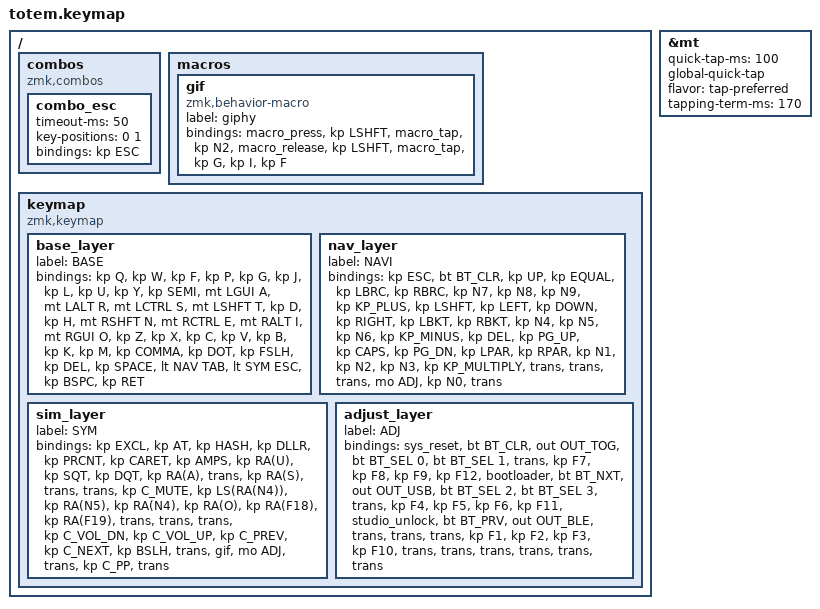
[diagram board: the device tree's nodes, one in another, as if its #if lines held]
//
//                                                        ▀▀▀▀▀     ▀▀▀▀▀          ▀▀█▀▀
//                                                        ▄▀▀▀▄  ▄  ▄▀▀▀▄  ▄  ▄▀▀▀▄  █  ▄▀▀▀▄
//                                                        █   █  █  █   █  █  █   █  █  █   █
//                                                         ▀▀▀   █   ▀▀▀   █   ▀▀▀   ▀   ▀▀▀
//                                                               █      ▄▄▄█▄▄▄    █   █  
//                                                               ▀      █  █  █     █▄█
//                                                             ▀▀▀▀▀    █  █  █      ▀
//                                                                      ▀  ▀  ▀
//
// ▄▄▄▄▄▄▄▄▄▄▄▄▄▄▄▄▄▄▄▄▄▄▄▄▄▄▄▄▄▄▄▄▄▄▄▄▄▄▄▄▄▄▄▄▄▄▄▄▄▄▄▄▄▄▄▄▄▄▄▄▄▄▄▄▄▄▄▄▄▄▄▄▄▄▄▄▄▄▄▄▄▄▄▄▄▄▄▄▄▄▄▄▄▄▄▄▄▄▄▄▄▄▄▄▄▄▄▄▄▄▄▄▄▄▄▄▄▄▄▄▄▄▄▄▄▄▄▄▄▄▄▄▄▄▄▄▄▄▄▄▄▄▄▄▄▄▄▄▄
       

#include <behaviors.dtsi>
#include <dt-bindings/zmk/keys.h>
#include <dt-bindings/zmk/bt.h>
#include <dt-bindings/zmk/outputs.h>

#define BASE 0
#define NAV  1
#define SYM  2
#define ADJ  3

&mt {
  quick-tap-ms = <100>;
  global-quick-tap;
  flavor = "tap-preferred";
  tapping-term-ms = <170>;
};

/ {
    combos {
            compatible = "zmk,combos";
            combo_esc {
                timeout-ms = <50>;
                key-positions = <0 1>;
                bindings = <&kp ESC>;
            };
    };

    macros {
        gif: gif {
            label = "giphy";
            compatible = "zmk,behavior-macro";
            #binding-cells = <0>;
            bindings
                = <&macro_press &kp LSHFT>
                , <&macro_tap &kp N2>
                , <&macro_release &kp LSHFT>
                , <&macro_tap &kp G &kp I &kp F>
                ;
        };
    };

        keymap {
                compatible = "zmk,keymap";
// ▄▄▄▄▄▄▄▄▄▄▄▄▄▄▄▄▄▄▄▄▄▄▄▄▄▄▄▄▄▄▄▄▄▄▄▄▄▄▄▄▄▄▄▄▄▄▄▄▄▄▄▄▄▄▄▄▄▄▄▄▄▄▄▄▄▄▄▄▄▄▄▄▄▄▄▄▄▄▄▄▄▄▄▄▄▄▄▄▄▄▄▄▄▄▄▄▄▄▄▄▄▄▄▄▄▄▄▄▄▄▄▄▄▄▄▄▄▄▄▄▄▄▄▄▄▄▄▄▄▄▄▄▄▄▄▄▄▄▄▄▄▄▄▄▄▄▄▄▄

                base_layer {
// ┏━━━━━━━━━━━━━━━━━━━━━━━━━━━━━━━━━━━━━━━┓
label= "BASE"                              ;
// ┗━━━━━━━━━━━━━━━━━━━━━━━━━━━━━━━━━━━━━━━┛
//             ┏━━━━━━━━━━━┳━━━━━━━━━━━┳━━━━━━━━━━━┳━━━━━━━━━━━┳━━━━━━━━━━━┓   ┏━━━━━━━━━━━┳━━━━━━━━━━━┳━━━━━━━━━━━┳━━━━━━━━━━━┳━━━━━━━━━━━┓
//             ┃     Q     ┃     W     ┃     F     ┃     P     ┃     G     ┃   ┃     J     ┃     L     ┃     U     ┃     Y     ┃     ;     ┃
//             ┣━━━━━━━━━━━╋━━━━━━━━━━━╋━━━━━━━━━━━╋━━━━━━━━━━━╋━━━━━━━━━━━┫   ┣━━━━━━━━━━━╋━━━━━━━━━━━╋━━━━━━━━━━━╋━━━━━━━━━━━╋━━━━━━━━━━━┫
//             ┃     A     ┃     R     ┃     S     ┃     T     ┃     D     ┃   ┃     H     ┃     N     ┃     E     ┃     I     ┃     O     ┃
// ┏━━━━━━━━━━━╋━━━━━━━━━━━╋━━━━━━━━━━━╋━━━━━━━━━━━╋━━━━━━━━━━━╋━━━━━━━━━━━┫   ┣━━━━━━━━━━━╋━━━━━━━━━━━╋━━━━━━━━━━━╋━━━━━━━━━━━╋━━━━━━━━━━━╋━━━━━━━━━━━┓
// ┃           ┃     Z     ┃     X     ┃     C     ┃     V     ┃     B     ┃   ┃     K     ┃     M     ┃     ,     ┃     .     ┃     /     ┃           ┃
// ┗━━━━━━━━━━━┻━━━━━━━━━━━┻━━━━━━━━━━━╋━━━━━━━━━━━╋━━━━━━━━━━━╋━━━━━━━━━━━┫   ┣━━━━━━━━━━━╋━━━━━━━━━━━╋━━━━━━━━━━━╋━━━━━━━━━━━┻━━━━━━━━━━━┻━━━━━━━━━━━┛
//                                     ┃    DEL    ┃   SPACE   ┃  TAB/NAV  ┃   ┃  ESC/SYM  ┃   BSPC    ┃   ENTER   ┃
//                                     ┗━━━━━━━━━━━┻━━━━━━━━━━━┻━━━━━━━━━━━┛   ┗━━━━━━━━━━━┻━━━━━━━━━━━┻━━━━━━━━━━━┛
 bindings = <
// ╷           ╷           ╷           ╷           ╷           ╷           ╷   ╷           ╷           ╷           ╷           ╷           ╷           ╷

                &kp Q       &kp W       &kp F       &kp P       &kp G           &kp J       &kp L       &kp U       &kp Y       &kp SEMI
                &mt LGUI A  &mt LALT R  &mt LCTRL S &mt LSHFT T &kp D           &kp H       &mt RSHFT N &mt RCTRL E &mt RALT I  &mt RGUI O
    &kp Z       &kp X       &kp C       &kp V       &kp B           &kp K       &kp M       &kp COMMA   &kp DOT     &kp FSLH    
                                        &kp DEL     &kp SPACE   &lt NAV TAB     &lt SYM ESC &kp BSPC    &kp RET
                        >;
                };

// ▄▄▄▄▄▄▄▄▄▄▄▄▄▄▄▄▄▄▄▄▄▄▄▄▄▄▄▄▄▄▄▄▄▄▄▄▄▄▄▄▄▄▄▄▄▄▄▄▄▄▄▄▄▄▄▄▄▄▄▄▄▄▄▄▄▄▄▄▄▄▄▄▄▄▄▄▄▄▄▄▄▄▄▄▄▄▄▄▄▄▄▄▄▄▄▄▄▄▄▄▄▄▄▄▄▄▄▄▄▄▄▄▄▄▄▄▄▄▄▄▄▄▄▄▄▄▄▄▄▄▄▄▄▄▄▄▄▄▄▄▄▄▄▄▄▄▄▄▄


                nav_layer {
// ┏━━━━━━━━━━━━━━━━━━━━━━━━━━━━━━━━━━━━━━━┓
label= "NAVI"                              ;
// ┗━━━━━━━━━━━━━━━━━━━━━━━━━━━━━━━━━━━━━━━┛
//             ┏━━━━━━━━━━━┳━━━━━━━━━━━┳━━━━━━━━━━━┳━━━━━━━━━━━┳━━━━━━━━━━━┓   ┏━━━━━━━━━━━┳━━━━━━━━━━━┳━━━━━━━━━━━┳━━━━━━━━━━━┳━━━━━━━━━━━┓
//             ┃           ┃           ┃     UP    ┃           ┃     {     ┃   ┃     }     ┃     7     ┃     8     ┃     9     ┃     +     ┃
//             ┣━━━━━━━━━━━╋━━━━━━━━━━━╋━━━━━━━━━━━╋━━━━━━━━━━━╋━━━━━━━━━━━┫   ┣━━━━━━━━━━━╋━━━━━━━━━━━╋━━━━━━━━━━━╋━━━━━━━━━━━╋━━━━━━━━━━━┫
//             ┃   SHIFT   ┃   LEFT    ┃    DOWN   ┃   RIGHT   ┃     [     ┃   ┃     ]     ┃     4     ┃     5     ┃     6     ┃     -     ┃
// ┏━━━━━━━━━━━╋━━━━━━━━━━━╋━━━━━━━━━━━╋━━━━━━━━━━━╋━━━━━━━━━━━╋━━━━━━━━━━━┫   ┣━━━━━━━━━━━╋━━━━━━━━━━━╋━━━━━━━━━━━╋━━━━━━━━━━━╋━━━━━━━━━━━╋━━━━━━━━━━━┓
// ┃           ┃           ┃   P UP    ┃  C LOCK   ┃  P DOWN   ┃     (     ┃   ┃     )     ┃     1     ┃     2     ┃     3     ┃     *     ┃           ┃
// ┗━━━━━━━━━━━┻━━━━━━━━━━━┻━━━━━━━━━━━╋━━━━━━━━━━━╋━━━━━━━━━━━╋━━━━━━━━━━━┫   ┣━━━━━━━━━━━╋━━━━━━━━━━━╋━━━━━━━━━━━╋━━━━━━━━━━━┻━━━━━━━━━━━┻━━━━━━━━━━━┛
//                                     ┃           ┃    TAB    ┃    SPC    ┃   ┃    DEL    ┃     0     ┃           ┃
//                                     ┗━━━━━━━━━━━┻━━━━━━━━━━━┻━━━━━━━━━━━┛   ┗━━━━━━━━━━━┻━━━━━━━━━━━┻━━━━━━━━━━━┛
 bindings = <
// ╷           ╷           ╷           ╷           ╷           ╷           ╷   ╷           ╷           ╷           ╷           ╷           ╷           ╷

                &kp ESC     &bt BT_CLR  &kp UP      &kp EQUAL   &kp LBRC        &kp RBRC    &kp N7      &kp N8      &kp N9      &kp KP_PLUS
                &kp LSHFT   &kp LEFT    &kp DOWN    &kp RIGHT   &kp LBKT        &kp RBKT    &kp N4      &kp N5      &kp N6      &kp KP_MINUS
    &kp DEL     &kp PG_UP   &kp CAPS    &kp PG_DN   &kp LPAR        &kp RPAR    &kp N1      &kp N2      &kp N3      &kp KP_MULTIPLY 
                                        &trans      &trans      &trans          &mo ADJ     &kp N0      &trans      
                        >;
                };

// ▄▄▄▄▄▄▄▄▄▄▄▄▄▄▄▄▄▄▄▄▄▄▄▄▄▄▄▄▄▄▄▄▄▄▄▄▄▄▄▄▄▄▄▄▄▄▄▄▄▄▄▄▄▄▄▄▄▄▄▄▄▄▄▄▄▄▄▄▄▄▄▄▄▄▄▄▄▄▄▄▄▄▄▄▄▄▄▄▄▄▄▄▄▄▄▄▄▄▄▄▄▄▄▄▄▄▄▄▄▄▄▄▄▄▄▄▄▄▄▄▄▄▄▄▄▄▄▄▄▄▄▄▄▄▄▄▄▄▄▄▄▄▄▄▄▄▄▄▄


                sim_layer {
// ┏━━━━━━━━━━━━━━━━━━━━━━━━━━━━━━━━━━━━━━━┓
label= "SYM"                               ;
// ┗━━━━━━━━━━━━━━━━━━━━━━━━━━━━━━━━━━━━━━━┛
//             ┏━━━━━━━━━━━┳━━━━━━━━━━━┳━━━━━━━━━━━┳━━━━━━━━━━━┳━━━━━━━━━━━┓   ┏━━━━━━━━━━━┳━━━━━━━━━━━┳━━━━━━━━━━━┳━━━━━━━━━━━┳━━━━━━━━━━━┓
//             ┃     !     ┃     @     ┃     #     ┃     $     ┃     %     ┃   ┃     ˆ     ┃     &     ┃     Ü     ┃     '     ┃     "     ┃
//             ┣━━━━━━━━━━━╋━━━━━━━━━━━╋━━━━━━━━━━━╋━━━━━━━━━━━╋━━━━━━━━━━━┫   ┣━━━━━━━━━━━╋━━━━━━━━━━━╋━━━━━━━━━━━╋━━━━━━━━━━━╋━━━━━━━━━━━┫
//             ┃     Ä     ┃           ┃    SZ     ┃           ┃           ┃   ┃   MUTE    ┃   YEN     ┃   EURO    ┃  POUND    ┃     Ö     ┃
// ┏━━━━━━━━━━━╋━━━━━━━━━━━╋━━━━━━━━━━━╋━━━━━━━━━━━╋━━━━━━━━━━━╋━━━━━━━━━━━┫   ┣━━━━━━━━━━━╋━━━━━━━━━━━╋━━━━━━━━━━━╋━━━━━━━━━━━╋━━━━━━━━━━━╋━━━━━━━━━━━┓
// ┃           ┃  EMAIL1   ┃  EMAIL2   ┃           ┃           ┃           ┃   ┃   VOL-    ┃   VOL+    ┃   LAST    ┃   NEXT    ┃     \     ┃           ┃
// ┗━━━━━━━━━━━┻━━━━━━━━━━━┻━━━━━━━━━━━╋━━━━━━━━━━━╋━━━━━━━━━━━╋━━━━━━━━━━━┫   ┣━━━━━━━━━━━╋━━━━━━━━━━━╋━━━━━━━━━━━╋━━━━━━━━━━━┻━━━━━━━━━━━┻━━━━━━━━━━━┛
//                                     ┃           ┃    GIF    ┃    ADJ    ┃   ┃           ┃           ┃           ┃
//                                     ┗━━━━━━━━━━━┻━━━━━━━━━━━┻━━━━━━━━━━━┛   ┗━━━━━━━━━━━┻━━━━━━━━━━━┻━━━━━━━━━━━┛
 bindings = <
// ╷           ╷           ╷           ╷           ╷           ╷           ╷   ╷           ╷           ╷           ╷           ╷           ╷           ╷

                &kp EXCL    &kp AT      &kp HASH    &kp DLLR    &kp PRCNT       &kp CARET   &kp AMPS    &kp RA(U)   &kp SQT     &kp DQT       
                &kp RA(A)   &trans      &kp RA(S)   &trans      &trans          &kp C_MUTE  &kp LS(RA(N4)) &kp RA(N5) &kp RA(N4)   &kp RA(O) 
    &kp RA(F18) &kp RA(F19) &trans      &trans      &trans          &kp C_VOL_DN &kp C_VOL_UP &kp C_PREV &kp C_NEXT  &kp BSLH   
                                        &trans      &gif        &mo ADJ         &trans      &kp C_PP    &trans      
                        >;
                };

// ▄▄▄▄▄▄▄▄▄▄▄▄▄▄▄▄▄▄▄▄▄▄▄▄▄▄▄▄▄▄▄▄▄▄▄▄▄▄▄▄▄▄▄▄▄▄▄▄▄▄▄▄▄▄▄▄▄▄▄▄▄▄▄▄▄▄▄▄▄▄▄▄▄▄▄▄▄▄▄▄▄▄▄▄▄▄▄▄▄▄▄▄▄▄▄▄▄▄▄▄▄▄▄▄▄▄▄▄▄▄▄▄▄▄▄▄▄▄▄▄▄▄▄▄▄▄▄▄▄▄▄▄▄▄▄▄▄▄▄▄▄▄▄▄▄▄▄▄▄


                adjust_layer {
// ┏━━━━━━━━━━━━━━━━━━━━━━━━━━━━━━━━━━━━━━━┓
label= "ADJ"                               ;
// ┗━━━━━━━━━━━━━━━━━━━━━━━━━━━━━━━━━━━━━━━┛
//             ┏━━━━━━━━━━━┳━━━━━━━━━━━┳━━━━━━━━━━━┳━━━━━━━━━━━┳━━━━━━━━━━━┓   ┏━━━━━━━━━━━┳━━━━━━━━━━━┳━━━━━━━━━━━┳━━━━━━━━━━━┳━━━━━━━━━━━┓
//             ┃   RESET   ┃ BT CLEAR  ┃  OUT TOG  ┃           ┃           ┃   ┃           ┃    F7     ┃    F8     ┃    F9     ┃    F12    ┃
//             ┣━━━━━━━━━━━╋━━━━━━━━━━━╋━━━━━━━━━━━╋━━━━━━━━━━━╋━━━━━━━━━━━┫   ┣━━━━━━━━━━━╋━━━━━━━━━━━╋━━━━━━━━━━━╋━━━━━━━━━━━╋━━━━━━━━━━━┫
//             ┃ BOOTLOAD  ┃ BT NEXT   ┃           ┃           ┃           ┃   ┃           ┃    F4     ┃    F5     ┃    F6     ┃    F11    ┃
// ┏━━━━━━━━━━━╋━━━━━━━━━━━╋━━━━━━━━━━━╋━━━━━━━━━━━╋━━━━━━━━━━━╋━━━━━━━━━━━┫   ┣━━━━━━━━━━━╋━━━━━━━━━━━╋━━━━━━━━━━━╋━━━━━━━━━━━╋━━━━━━━━━━━╋━━━━━━━━━━━┓
// ┃           ┃           ┃ BT PREV   ┃           ┃           ┃           ┃   ┃           ┃    F1     ┃    F2     ┃    F3     ┃    F10    ┃           ┃
// ┗━━━━━━━━━━━┻━━━━━━━━━━━┻━━━━━━━━━━━╋━━━━━━━━━━━╋━━━━━━━━━━━╋━━━━━━━━━━━┫   ┣━━━━━━━━━━━╋━━━━━━━━━━━╋━━━━━━━━━━━╋━━━━━━━━━━━┻━━━━━━━━━━━┻━━━━━━━━━━━┛
//                                     ┃           ┃           ┃           ┃   ┃           ┃           ┃           ┃
//                                     ┗━━━━━━━━━━━┻━━━━━━━━━━━┻━━━━━━━━━━━┛   ┗━━━━━━━━━━━┻━━━━━━━━━━━┻━━━━━━━━━━━┛
 bindings = <
// ╷           ╷           ╷           ╷           ╷           ╷           ╷   ╷           ╷           ╷           ╷           ╷           ╷           ╷

                &sys_reset  &bt BT_CLR &out OUT_TOG &bt BT_SEL 0 &bt BT_SEL 1          &trans      &kp F7      &kp F8      &kp F9      &kp F12
                &bootloader &bt BT_NXT  &out OUT_USB &bt BT_SEL 2 &bt BT_SEL 3          &trans      &kp F4      &kp F5      &kp F6      &kp F11  
#ifdef CONFIG_ZMK_STUDIO
    &studio_unlock
#else
    &trans
#endif
                &bt BT_PRV  &out OUT_BLE &trans      &trans          &trans      &kp F1      &kp F2      &kp F3      &kp F10     
                                        &trans      &trans      &trans          &trans      &trans      &trans      
                        >;
                };
        };
};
